# soc register map
Vendor: litex
Registers are 32-bit, read-write, reset 0x0 unless marked. A register's access mark holds for its fields unless they carry their own. Offsets are from the block's base; lines under a group give offsets from that group; [hi:lo] are bit positions; {n}, {i} and the like mark numbered series; 'fields as' and 'values as' point back to an identical list; <NAME> marks a mode.

## Memory map
0xE0000000 CTRL size 0xC
0xE0001000 UART_PHY size 0x4
0xE0001800 UART size 0x20
0xE0002000 TIMER0 size 0x20
0xE0002800 SPIFLASH size 0xC
0xE0003000 CLOCK size 0x4
0xE0003800 GPIO size 0x18

## Further device data
memoryRegions:
  SRAM baseAddress=0x10000000 size=0x00020000
  SPIFLASH baseAddress=0x20000000 size=0x01000000
  ROM baseAddress=0x20040000 size=0x00FC0000
  CSR baseAddress=0xE0000000 size=0x00010000

## CTRL
Base 0xE0000000
0x00 RESET — Any write to this register will reset the SoC.
  [0] reset
0x04 SCRATCH reset 0x12345678 — Use this register as a scratch space to verify that software read/write accesses to the Wishbone/CSR bus are working correctly. The initial reset value of 0x1234578 can be used to verify endianness.
0x08 BUS_ERRORS — Total number of Wishbone bus errors (timeouts) since start.

## UART_PHY
Base 0xE0001000
0x00 TUNING_WORD reset 0x1678303

## UART
Base 0xE0001800
0x00 RXTX
  [7:0] rxtx
0x04 TXFULL
  [0] txfull
0x08 RXEMPTY
  [0] rxempty
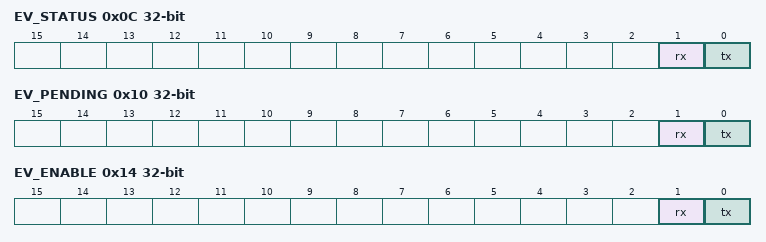
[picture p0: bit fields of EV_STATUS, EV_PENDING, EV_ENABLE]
0x0C EV_STATUS — This register contains the current raw level of the rx event trigger. Writes to this register have no effect.
  [1] rx — Level of the ``rx`` event
  [0] tx — Level of the ``tx`` event
0x10 EV_PENDING — When a rx event occurs, the corresponding bit will be set in this register. To clear the Event, set the corresponding bit in this register.
  [1] rx — `1` if a `rx` event occurred. This Event is triggered on a **falling** edge.
  [0] tx — `1` if a `tx` event occurred. This Event is triggered on a **falling** edge.
0x14 EV_ENABLE — This register enables the corresponding rx events. Write a ``0`` to this register to disable individual events.
  [1] rx — Write a ``1`` to enable the ``rx`` Event
  [0] tx — Write a ``1`` to enable the ``tx`` Event
0x18 TXEMPTY
  [0] txempty
0x1C RXFULL
  [0] rxfull

## TIMER0
Base 0xE0002000
0x00 LOAD — Load value when Timer is (re-)enabled. In One-Shot mode, the value written to this register specifies the Timer's duration in clock cycles.
0x04 RELOAD — Reload value when Timer reaches ``0``. In Periodic mode, the value written to this register specify the Timer's period in clock cycles.
0x08 EN — Enable flag of the Timer. Set this flag to ``1`` to enable/start the Timer. Set to ``0`` to disable the Timer.
  [0] en
0x0C UPDATE_VALUE — Update trigger for the current countdown value. A write to this register latches the current countdown value to ``value`` register.
  [0] update_value
0x10 VALUE — Latched countdown value. This value is updated by writing to ``update_value``.
0x14 EV_STATUS — This register contains the current raw level of the zero event trigger. Writes to this register have no effect.
  [0] zero — Level of the ``zero`` event
0x18 EV_PENDING — When a zero event occurs, the corresponding bit will be set in this register. To clear the Event, set the corresponding bit in this register.
  [0] zero — `1` if a `zero` event occurred. This Event is triggered on a **falling** edge.
0x1C EV_ENABLE — This register enables the corresponding zero events. Write a ``0`` to this register to disable individual events.
  [0] zero — Write a ``1`` to enable the ``zero`` Event

## SPIFLASH
Base 0xE0002800
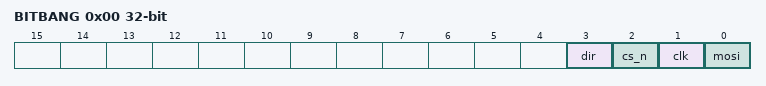
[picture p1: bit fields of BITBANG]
0x00 BITBANG — Bitbang controls for SPI output. Only standard 1x SPI is supported, and as a result all four wires are ganged together. This means that it is only possible to perform half-duplex operations, using this SPI core.
  [3] dir — Sets the direction for *ALL* SPI data pins except CLK and CSn.
  [2] cs_n — Output value for SPI CSn pin.
  [1] clk — Output value for SPI CLK pin.
  [0] mosi — Output value for MOSI pin, valid whenever ``dir`` is ``0``.
0x04 MISO — Incoming value of MISO signal.
  [0] miso
0x08 BITBANG_EN — Write a ``1`` here to disable memory-mapped mode and enable bitbang mode.
  [0] bitbang_en

## CLOCK
Base 0xE0003000
0x00 CORECLK — Core clock frequency

## GPIO
Base 0xE0003800
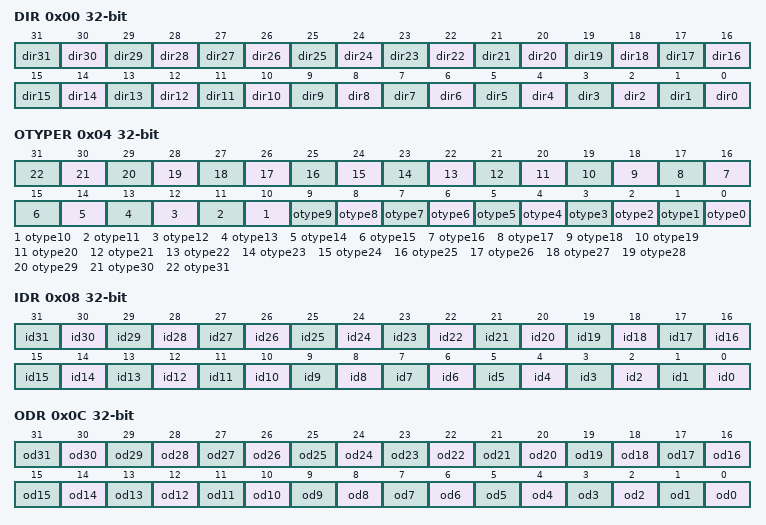
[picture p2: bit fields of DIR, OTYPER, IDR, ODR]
0x00 DIR — GPIO pin direction
  [n] dir{n} (n=0..31) — Pin direction
0x04 OTYPER — GPIO output type register
  [n] otype{n} (n=0..31) — Pin output type
0x08 IDR — GPIO input data register
  [n] id{n} (n=0..31) — Pin input data
0x0C ODR — GPIO output data register
  [n] od{n} (n=0..31) — Pin output data
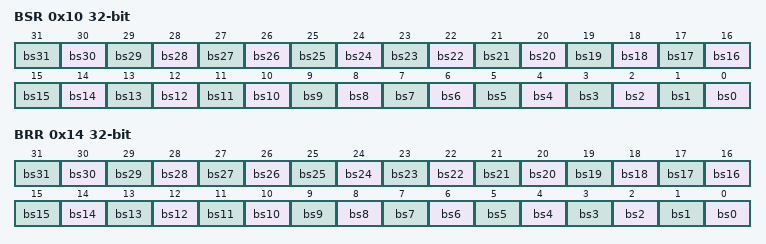
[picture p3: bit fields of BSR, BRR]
0x10 BSR — GPIO bit set register
  [n] bs{n} (n=0..31) — Pin set bit
0x14 BRR — GPIO bit reset register
  [n] bs{n} (n=0..31) — Pin reset bit
